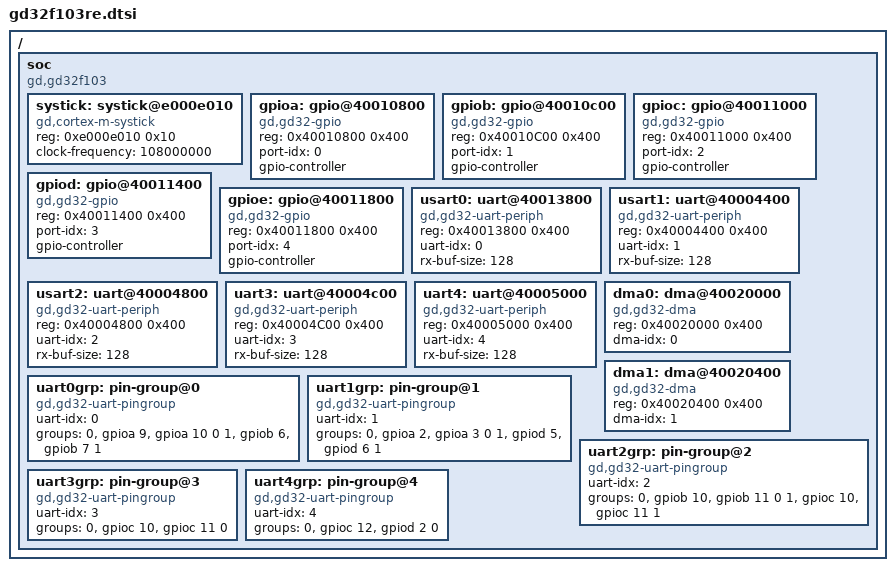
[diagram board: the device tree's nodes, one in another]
/*
 * gd32f103re.dtsi —— SoC 级设备树(芯片外设), 由板级 .dts include
 *
 * port-idx : 端口序号, 驱动内用它索引 GPIOA~GPIOE 基址/时钟表
 *            (A=0, B=1, C=2, D=3, E=4)
 * #gpio-cells = 2 : 引用格式为 <&gpiox 引脚号 模式>
 */

#include <dt-bindings/gpio/gd32f10x-gpio.h>
#include <dt-bindings/serial/gd32f10x-uart.h>

/ {
	#address-cells = <1>;
	#size-cells = <1>;

	soc {
		compatible = "gd,gd32f103";
		#address-cells = <1>;
		#size-cells = <1>;

		/* Cortex-M3 内核 SysTick: clock-frequency 描述 CPU 时钟(延时基准),
		 * 与 vendor 的 __SYSTEM_CLOCK_108M_PLL 一致; 板卡换主频时在板级 dts 覆写 */
		systick: systick@e000e010 {
			compatible = "gd,cortex-m-systick";
			reg = <0xe000e010 0x10>;
			clock-frequency = <108000000>;
		};

		gpioa: gpio@40010800 {
			compatible = "gd,gd32-gpio";
			reg = <0x40010800 0x400>;
			port-idx = <0>;
			#gpio-cells = <2>;
			gpio-controller;
		};

		gpiob: gpio@40010c00 {
			compatible = "gd,gd32-gpio";
			reg = <0x40010C00 0x400>;
			port-idx = <1>;
			#gpio-cells = <2>;
			gpio-controller;
		};

		gpioc: gpio@40011000 {
			compatible = "gd,gd32-gpio";
			reg = <0x40011000 0x400>;
			port-idx = <2>;
			#gpio-cells = <2>;
			gpio-controller;
		};

		gpiod: gpio@40011400 {
			compatible = "gd,gd32-gpio";
			reg = <0x40011400 0x400>;
			port-idx = <3>;
			#gpio-cells = <2>;
			gpio-controller;
		};

		gpioe: gpio@40011800 {
			compatible = "gd,gd32-gpio";
			reg = <0x40011800 0x400>;
			port-idx = <4>;
			#gpio-cells = <2>;
			gpio-controller;
		};

		/* ------------------------------------------------------------------
		 * USART/UART 外设节点
		 *
		 * reg        : 外设基址 (USART0=0x40013800(APB2), 其余在 APB1)
		 * uart-idx   : 驱动内索引用序号 (0=USART0 ... 4=UART4)
		 * rx-buf-size: RX 环形缓冲区字节数 (DMA/中断接收的数据落地处)
		 *
		 * 引脚分组 (pin-groups): 每个 uart 节点下带若干组预定义引脚组合,
		 * 板级 dts 用 pinctrl-x 引用其中一组(默认 m0); 也可以不用预定义组,
		 * 直接在板级 dts 里写 pinctrl 手动组合 TX/RX 引脚(数据手册 2.6 节
		 * 中所有标了 USARTx_TX / USARTx_RX 复用功能的引脚均可)。
		 * ------------------------------------------------------------------ */
		usart0: uart@40013800 {
			compatible = "gd,gd32-uart-periph";
			reg = <0x40013800 0x400>;
			uart-idx = <0>;
			rx-buf-size = <128>;
			#pin-group-cells = <1>;
		};

		usart1: uart@40004400 {
			compatible = "gd,gd32-uart-periph";
			reg = <0x40004400 0x400>;
			uart-idx = <1>;
			rx-buf-size = <128>;
			#pin-group-cells = <1>;
		};

		usart2: uart@40004800 {
			compatible = "gd,gd32-uart-periph";
			reg = <0x40004800 0x400>;
			uart-idx = <2>;
			rx-buf-size = <128>;
			#pin-group-cells = <1>;
		};

		uart3: uart@40004c00 {
			compatible = "gd,gd32-uart-periph";
			reg = <0x40004C00 0x400>;
			uart-idx = <3>;
			rx-buf-size = <128>;
			#pin-group-cells = <1>;
		};

		uart4: uart@40005000 {
			compatible = "gd,gd32-uart-periph";
			reg = <0x40005000 0x400>;
			uart-idx = <4>;
			rx-buf-size = <128>;
			#pin-group-cells = <1>;
		};

		dma0: dma@40020000 {
			compatible = "gd,gd32-dma";
			reg = <0x40020000 0x400>;
			dma-idx = <0>;
		};

		dma1: dma@40020400 {
			compatible = "gd,gd32-dma";
			reg = <0x40020400 0x400>;
			dma-idx = <1>;
		};

		/* ------------------------------------------------------------------
		 * UART 引脚分组 (借用 Linux pinctrl 思想): 把数据手册 2.6 节中
		 * 每个串口可选的 TX/RX 引脚组合预定义成组, 板级 dts 用
		 * pgroup = <&usart0 0> 选择; 第 2 个单元是组号:
		 *   0 = m0 默认组 (USART0: PA9/PA10, USART1: PA2/PA3, ...)
		 *   1 = m1 重映射组 (USART0: PB6/PB7, USART2: PC10/PC11, ...)
		 * 用户也可以不用预定义组, 在板级 dts 直接写 tx-gpios/rx-gpios
		 * 手动组合 (例如 PA9 搭配 PB7), 只要引脚在数据手册中标了对应
		 * 的 USARTx_TX/RX 复用功能即可。
		 * ------------------------------------------------------------------ */
		uart0grp: pin-group@0 {
			compatible = "gd,gd32-uart-pingroup";
			uart-idx = <0>;
			groups = <
				/* m0: PA9=USART0_TX,  PA10=USART0_RX (默认, 不重映射) */
				0 &gpioa 9 &gpioa 10 0
				/* m1: PB6=USART0_TX,  PB7=USART0_RX  (重映射) */
				1 &gpiob 6 &gpiob 7 1>;
		};

		uart1grp: pin-group@1 {
			compatible = "gd,gd32-uart-pingroup";
			uart-idx = <1>;
			groups = <
				/* m0: PA2=USART1_TX, PA3=USART1_RX (默认) */
				0 &gpioa 2 &gpioa 3 0
				/* m1: PD5=USART1_TX, PD6=USART1_RX (重映射, 仅 100/144 脚) */
				1 &gpiod 5 &gpiod 6 1>;
		};

		uart2grp: pin-group@2 {
			compatible = "gd,gd32-uart-pingroup";
			uart-idx = <2>;
			groups = <
				/* m0: PB10=USART2_TX, PB11=USART2_RX (默认) */
				0 &gpiob 10 &gpiob 11 0
				/* m1: PC10=USART2_TX, PC11=USART2_RX (部分重映射, 64 脚可用) */
				1 &gpioc 10 &gpioc 11 1>;
		};

		uart3grp: pin-group@3 {
			compatible = "gd,gd32-uart-pingroup";
			uart-idx = <3>;
			groups = <
				/* m0: PC10=UART3_TX, PC11=UART3_RX (固定, 无重映射) */
				0 &gpioc 10 &gpioc 11 0>;
		};

		uart4grp: pin-group@4 {
			compatible = "gd,gd32-uart-pingroup";
			uart-idx = <4>;
			groups = <
				/* m0: PC12=UART4_TX, PD2=UART4_RX (固定, 无重映射) */
				0 &gpioc 12 &gpiod 2 0>;
		};
	};
};
